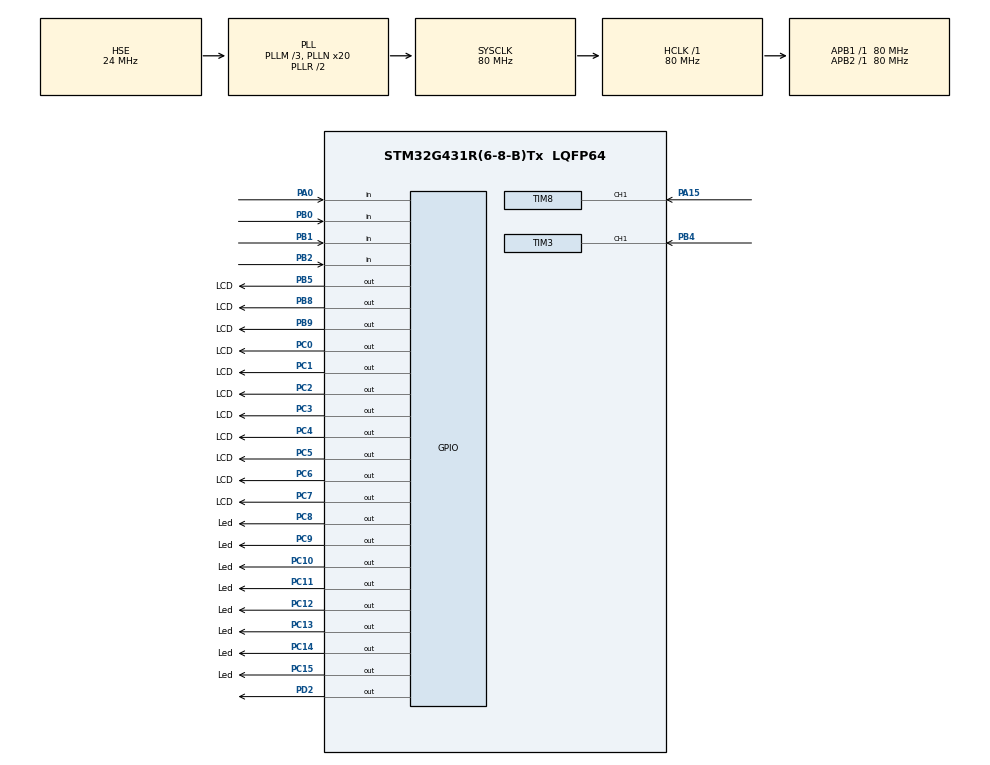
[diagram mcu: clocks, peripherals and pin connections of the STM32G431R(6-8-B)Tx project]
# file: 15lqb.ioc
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Mcu.Family=STM32G4
Mcu.Name=STM32G431R(6-8-B)Tx
Mcu.Package=LQFP64
NVIC.PriorityGroup=NVIC_PRIORITYGROUP_4
NVIC.TIM3_IRQn=true\:5\:0\:true\:false\:true\:true\:true\:true
NVIC.TIM6_DAC_IRQn=true\:0\:0\:false\:false\:true\:true\:true\:true
NVIC.TIM8_BRK_IRQn=true\:5\:0\:true\:false\:true\:true\:true\:true
NVIC.TIM8_CC_IRQn=true\:5\:0\:true\:false\:true\:true\:true\:true
NVIC.TIM8_TRG_COM_IRQn=true\:5\:0\:true\:false\:true\:true\:true\:true
NVIC.TIM8_UP_IRQn=true\:5\:0\:true\:false\:true\:true\:true\:true
PA0.Signal=GPIO_Input
PA13.Mode=Serial_Wire
PA13.Signal=SYS_JTMS-SWDIO
PA14.Mode=Serial_Wire
PA14.Signal=SYS_JTCK-SWCLK
PA15.Signal=S_TIM8_CH1
PB0.Signal=GPIO_Input
PB1.Signal=GPIO_Input
PB2.Signal=GPIO_Input
PB4.Signal=S_TIM3_CH1
PB5.GPIO_Label=LCD
PB5.GPIO_ModeDefaultOutputPP=GPIO_MODE_OUTPUT_PP
PB5.GPIO_PuPd=GPIO_NOPULL
PB5.GPIO_Speed=GPIO_SPEED_FREQ_LOW
PB5.PinState=GPIO_PIN_RESET
PB5.Signal=GPIO_Output
PB8-BOOT0.GPIO_Label=LCD
PB8-BOOT0.GPIO_ModeDefaultOutputPP=GPIO_MODE_OUTPUT_PP
PB8-BOOT0.GPIO_PuPd=GPIO_NOPULL
PB8-BOOT0.GPIO_Speed=GPIO_SPEED_FREQ_LOW
PB8-BOOT0.PinState=GPIO_PIN_RESET
PB8-BOOT0.Signal=GPIO_Output
PB9.GPIO_Label=LCD
PB9.GPIO_ModeDefaultOutputPP=GPIO_MODE_OUTPUT_PP
PB9.GPIO_PuPd=GPIO_NOPULL
PB9.GPIO_Speed=GPIO_SPEED_FREQ_LOW
PB9.PinState=GPIO_PIN_RESET
PB9.Signal=GPIO_Output
PC0.GPIO_Label=LCD
PC0.GPIO_ModeDefaultOutputPP=GPIO_MODE_OUTPUT_PP
PC0.GPIO_PuPd=GPIO_NOPULL
PC0.GPIO_Speed=GPIO_SPEED_FREQ_LOW
PC0.PinState=GPIO_PIN_RESET
PC0.Signal=GPIO_Output
PC1.GPIO_Label=LCD
PC1.GPIO_ModeDefaultOutputPP=GPIO_MODE_OUTPUT_PP
PC1.GPIO_PuPd=GPIO_NOPULL
PC1.GPIO_Speed=GPIO_SPEED_FREQ_LOW
PC1.PinState=GPIO_PIN_RESET
PC1.Signal=GPIO_Output
PC10.GPIO_Label=Led
PC10.GPIO_ModeDefaultOutputPP=GPIO_MODE_OUTPUT_PP
PC10.GPIO_PuPd=GPIO_PULLUP
PC10.GPIO_Speed=GPIO_SPEED_FREQ_LOW
PC10.PinState=GPIO_PIN_RESET
PC10.Signal=GPIO_Output
PC11.GPIO_Label=Led
PC11.GPIO_ModeDefaultOutputPP=GPIO_MODE_OUTPUT_PP
PC11.GPIO_PuPd=GPIO_PULLUP
PC11.GPIO_Speed=GPIO_SPEED_FREQ_LOW
PC11.PinState=GPIO_PIN_RESET
PC11.Signal=GPIO_Output
PC12.GPIO_Label=Led
PC12.GPIO_ModeDefaultOutputPP=GPIO_MODE_OUTPUT_PP
PC12.GPIO_PuPd=GPIO_PULLUP
PC12.GPIO_Speed=GPIO_SPEED_FREQ_LOW
PC12.PinState=GPIO_PIN_RESET
PC12.Signal=GPIO_Output
PC13.GPIO_Label=Led
PC13.GPIO_ModeDefaultOutputPP=GPIO_MODE_OUTPUT_PP
PC13.GPIO_PuPd=GPIO_PULLUP
PC13.GPIO_Speed=GPIO_SPEED_FREQ_LOW
PC13.PinState=GPIO_PIN_RESET
PC13.Signal=GPIO_Output
PC14-OSC32_IN.GPIO_Label=Led
PC14-OSC32_IN.GPIO_ModeDefaultOutputPP=GPIO_MODE_OUTPUT_PP
PC14-OSC32_IN.GPIO_PuPd=GPIO_PULLUP
PC14-OSC32_IN.GPIO_Speed=GPIO_SPEED_FREQ_LOW
PC14-OSC32_IN.PinState=GPIO_PIN_RESET
PC14-OSC32_IN.Signal=GPIO_Output
PC15-OSC32_OUT.GPIO_Label=Led
PC15-OSC32_OUT.GPIO_ModeDefaultOutputPP=GPIO_MODE_OUTPUT_PP
PC15-OSC32_OUT.GPIO_PuPd=GPIO_PULLUP
PC15-OSC32_OUT.GPIO_Speed=GPIO_SPEED_FREQ_LOW
PC15-OSC32_OUT.PinState=GPIO_PIN_RESET
PC15-OSC32_OUT.Signal=GPIO_Output
PC2.GPIO_Label=LCD
PC2.GPIO_ModeDefaultOutputPP=GPIO_MODE_OUTPUT_PP
PC2.GPIO_PuPd=GPIO_NOPULL
PC2.GPIO_Speed=GPIO_SPEED_FREQ_LOW
PC2.PinState=GPIO_PIN_RESET
PC2.Signal=GPIO_Output
PC3.GPIO_Label=LCD
PC3.GPIO_ModeDefaultOutputPP=GPIO_MODE_OUTPUT_PP
PC3.GPIO_PuPd=GPIO_NOPULL
PC3.GPIO_Speed=GPIO_SPEED_FREQ_LOW
PC3.PinState=GPIO_PIN_RESET
PC3.Signal=GPIO_Output
PC4.GPIO_Label=LCD
PC4.GPIO_ModeDefaultOutputPP=GPIO_MODE_OUTPUT_PP
PC4.GPIO_PuPd=GPIO_NOPULL
PC4.GPIO_Speed=GPIO_SPEED_FREQ_LOW
PC4.PinState=GPIO_PIN_RESET
PC4.Signal=GPIO_Output
PC5.GPIO_Label=LCD
PC5.GPIO_ModeDefaultOutputPP=GPIO_MODE_OUTPUT_PP
PC5.GPIO_PuPd=GPIO_NOPULL
PC5.GPIO_Speed=GPIO_SPEED_FREQ_LOW
PC5.PinState=GPIO_PIN_RESET
PC5.Signal=GPIO_Output
PC6.GPIO_Label=LCD
PC6.GPIO_ModeDefaultOutputPP=GPIO_MODE_OUTPUT_PP
PC6.GPIO_PuPd=GPIO_NOPULL
PC6.GPIO_Speed=GPIO_SPEED_FREQ_LOW
PC6.PinState=GPIO_PIN_RESET
PC6.Signal=GPIO_Output
PC7.GPIO_Label=LCD
PC7.GPIO_ModeDefaultOutputPP=GPIO_MODE_OUTPUT_PP
PC7.GPIO_PuPd=GPIO_NOPULL
PC7.GPIO_Speed=GPIO_SPEED_FREQ_LOW
PC7.PinState=GPIO_PIN_RESET
PC7.Signal=GPIO_Output
PC8.GPIO_Label=Led
PC8.GPIO_ModeDefaultOutputPP=GPIO_MODE_OUTPUT_PP
PC8.GPIO_PuPd=GPIO_PULLUP
PC8.GPIO_Speed=GPIO_SPEED_FREQ_LOW
PC8.PinState=GPIO_PIN_RESET
PC8.Signal=GPIO_Output
PC9.GPIO_Label=Led
PC9.GPIO_ModeDefaultOutputPP=GPIO_MODE_OUTPUT_PP
PC9.GPIO_PuPd=GPIO_PULLUP
PC9.GPIO_Speed=GPIO_SPEED_FREQ_LOW
PC9.PinState=GPIO_PIN_RESET
PC9.Signal=GPIO_Output
PD2.Signal=GPIO_Output
PF0-OSC_IN.Mode=HSE-External-Oscillator
PF0-OSC_IN.Signal=RCC_OSC_IN
PF1-OSC_OUT.Mode=HSE-External-Oscillator
PF1-OSC_OUT.Signal=RCC_OSC_OUT
ProjectManager.HeapSize=0x200
ProjectManager.StackSize=0x400
ProjectManager.TargetToolchain=MDK-ARM V5.32
RCC.ADC12Freq_Value=80000000
RCC.AHBFreq_Value=80000000
RCC.APB1Freq_Value=80000000
RCC.APB1TimFreq_Value=80000000
RCC.APB2Freq_Value=80000000
RCC.APB2TimFreq_Value=80000000
RCC.CortexFreq_Value=80000000
RCC.EXTERNAL_CLOCK_VALUE=12288000
RCC.HCLKFreq_Value=80000000
RCC.HSE_VALUE=24000000
RCC.HSI48_VALUE=48000000
RCC.HSI_VALUE=16000000
RCC.LSE_VALUE=32768
RCC.PLLM=RCC_PLLM_DIV3
RCC.PLLN=20
RCC.PLLSourceVirtual=RCC_PLLSOURCE_HSE
RCC.SYSCLKFreq_VALUE=80000000
RCC.SYSCLKSource=RCC_SYSCLKSOURCE_PLLCLK
RCC.USBFreq_Value=80000000
RCC.VCOOutputFreq_Value=160000000
SH.S_TIM3_CH1.0=TIM3_CH1,Input_Capture1_from_TI1
SH.S_TIM8_CH1.0=TIM8_CH1,Input_Capture1_from_TI1
TIM3.Channel-Input_Capture1_from_TI1=TIM_CHANNEL_1
TIM3.Prescaler=80-1
TIM6.PeriodNoDither=1000-1
TIM6.Prescaler=80-1
TIM8.Channel-Input_Capture1_from_TI1=TIM_CHANNEL_1
TIM8.Prescaler=80-1
VP_SYS_VS_DBSignals.Mode=DisableDeadBatterySignals
VP_TIM6_VS_ClockSourceINT.Mode=Enable_Timer
board=custom

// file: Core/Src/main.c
/* USER CODE BEGIN Header */
/**
  ******************************************************************************
  * @file           : main.c
  * @brief          : Main program body
  ******************************************************************************
  * @attention
  *
  * Copyright (c) 2026 STMicroelectronics.
  * All rights reserved.
  *
  * This software is licensed under terms that can be found in the LICENSE file
  * in the root directory of this software component.
  * If no LICENSE file comes with this software, it is provided AS-IS.
  *
  ******************************************************************************
  */
/* USER CODE END Header */
#include "main.h"
#include "tim.h"
#include "gpio.h"

/* USER CODE BEGIN Includes */
char text[30];
/* USER CODE END Includes */

void SystemClock_Config(void);

int main(void)
{

  /* MCU Configuration--------------------------------------------------------*/

  /* Reset of all peripherals, Initializes the Flash interface and the Systick. */
  HAL_Init();

  /* Configure the system clock */
  SystemClock_Config();

  /* Initialize all configured peripherals */
  MX_GPIO_Init();
  MX_TIM6_Init();
  MX_TIM3_Init();
  MX_TIM8_Init();
  /* USER CODE BEGIN 2 */
	task_init();

  /* USER CODE END 2 */

  /* Infinite loop */
  /* USER CODE BEGIN WHILE */
  while (1)
  {
		task_loop();
    /* USER CODE END WHILE */

  }
}

void SystemClock_Config(void)
{
  RCC_OscInitTypeDef RCC_OscInitStruct = {0};
  RCC_ClkInitTypeDef RCC_ClkInitStruct = {0};

  /** Configure the main internal regulator output voltage
  */
  HAL_PWREx_ControlVoltageScaling(PWR_REGULATOR_VOLTAGE_SCALE1);

  /** Initializes the RCC Oscillators according to the specified parameters
  * in the RCC_OscInitTypeDef structure.
  */
  RCC_OscInitStruct.OscillatorType = RCC_OSCILLATORTYPE_HSE;
  RCC_OscInitStruct.HSEState = RCC_HSE_ON;
  RCC_OscInitStruct.PLL.PLLState = RCC_PLL_ON;
  RCC_OscInitStruct.PLL.PLLSource = RCC_PLLSOURCE_HSE;
  RCC_OscInitStruct.PLL.PLLM = RCC_PLLM_DIV3;
  RCC_OscInitStruct.PLL.PLLN = 20;
  RCC_OscInitStruct.PLL.PLLP = RCC_PLLP_DIV2;
  RCC_OscInitStruct.PLL.PLLQ = RCC_PLLQ_DIV2;
  RCC_OscInitStruct.PLL.PLLR = RCC_PLLR_DIV2;
  if (HAL_RCC_OscConfig(&RCC_OscInitStruct) != HAL_OK)
  {
    Error_Handler();
  }

  /** Initializes the CPU, AHB and APB buses clocks
  */
  RCC_ClkInitStruct.ClockType = RCC_CLOCKTYPE_HCLK|RCC_CLOCKTYPE_SYSCLK
                              |RCC_CLOCKTYPE_PCLK1|RCC_CLOCKTYPE_PCLK2;
  RCC_ClkInitStruct.SYSCLKSource = RCC_SYSCLKSOURCE_PLLCLK;
  RCC_ClkInitStruct.AHBCLKDivider = RCC_SYSCLK_DIV1;
  RCC_ClkInitStruct.APB1CLKDivider = RCC_HCLK_DIV1;
  RCC_ClkInitStruct.APB2CLKDivider = RCC_HCLK_DIV1;

  if (HAL_RCC_ClockConfig(&RCC_ClkInitStruct, FLASH_LATENCY_2) != HAL_OK)
  {
    Error_Handler();
  }
}

void Error_Handler(void)
{
  __disable_irq();
  while (1)
  {
  }
}
